AUTOSAR XML (schema 4-2-1)
package /RootP_ASWC_M740
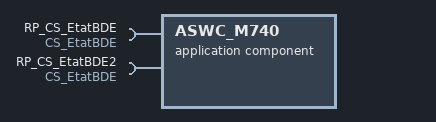
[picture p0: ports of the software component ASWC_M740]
  application sw component type ASWC_M740
    require port RP_CS_EtatBDE: required-interface=CS_EtatBDE
    require port RP_CS_EtatBDE2: required-interface=CS_EtatBDE
package /RootP_Composition
  composition sw component type Compo_VSM
    component Instance_ASWC_M740: type=ASWC_M740
